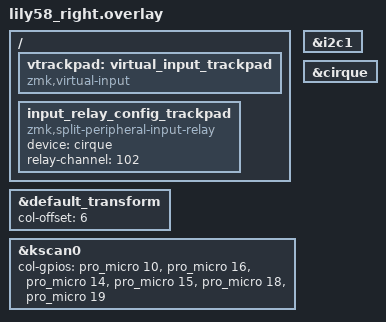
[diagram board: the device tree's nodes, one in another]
/*
 * Copyright (c) 2020 Pete Johanson
 *
 * SPDX-License-Identifier: MIT
 */

#include "lily58.dtsi"

&default_transform {
    col-offset = <6>;
};

&kscan0 {
    col-gpios
        = <&pro_micro 10 GPIO_ACTIVE_HIGH>
        , <&pro_micro 16 GPIO_ACTIVE_HIGH>
        , <&pro_micro 14 GPIO_ACTIVE_HIGH>
        , <&pro_micro 15 GPIO_ACTIVE_HIGH>
        , <&pro_micro 18 GPIO_ACTIVE_HIGH>
        , <&pro_micro 19 GPIO_ACTIVE_HIGH>
        ;
};

&i2c1 {
  status="okay";
};


&cirque {
  status="okay";
};


/ {
	vtrackpad: virtual_input_trackpad {
		compatible = "zmk,virtual-input";
	};

	input_relay_config_trackpad {
		compatible = "zmk,split-peripheral-input-relay";
		device = <&cirque>;
		relay-channel = <102>;
	};
};
